VERSION "1.0"

NS_ :

BS_:
BU_:

CM_ "For Preparatory Truma Messages
Author: Damiano Liviero
for Winnebago Industries Inc.
";

CM_ "1FDCD";
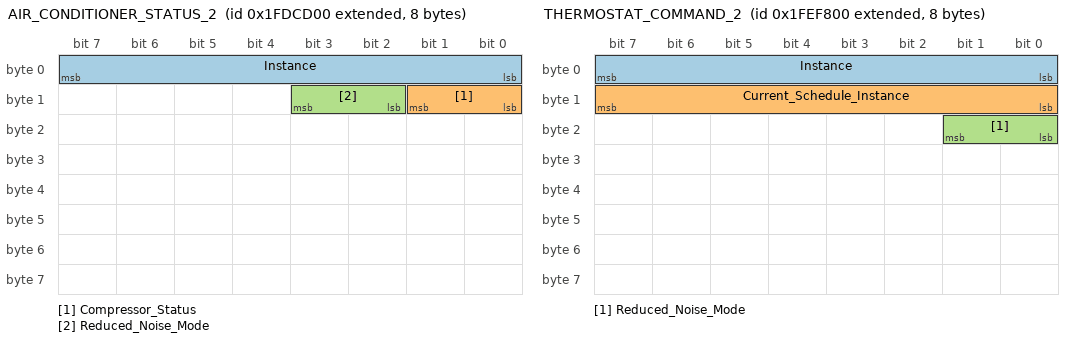
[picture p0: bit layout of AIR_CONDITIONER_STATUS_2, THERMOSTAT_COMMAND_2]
BO_ 2180893952 AIR_CONDITIONER_STATUS_2: 8  Vector__XXX
    SG_ Instance:        0|8@1+  (1,0)   [0|255] ""    Vector__XXX
    SG_ Compressor_Status:        8|2@1+  (1,0)   [0|3] ""    Vector__XXX
    SG_ Reduced_Noise_Mode:        10|2@1+  (1,0)   [0|3] ""    Vector__XXX

    0 "Off"
    1 "Compressor intends to start"
    2 "Compressor is starting"
    3 "Compressor is running";

    0 "Disabled"
    1 "Enabled"
    3 "Data Invalid";

CM_ "1FEF8";
BO_ 2180970496 THERMOSTAT_COMMAND_2: 8  Vector__XXX
    SG_ Instance:        0|8@1+  (1,0)   [0|255] ""    Vector__XXX
    SG_ Current_Schedule_Instance:        8|8@1+  (1,0)   [0|255] ""    Vector__XXX
    SG_ Reduced_Noise_Mode:        16|2@1+  (1,0)   [0|3] ""    Vector__XXX

    251 "Reset to current instance";

    0 "disabled"
    1 "Enabled"
    3 "Data Invalid";
